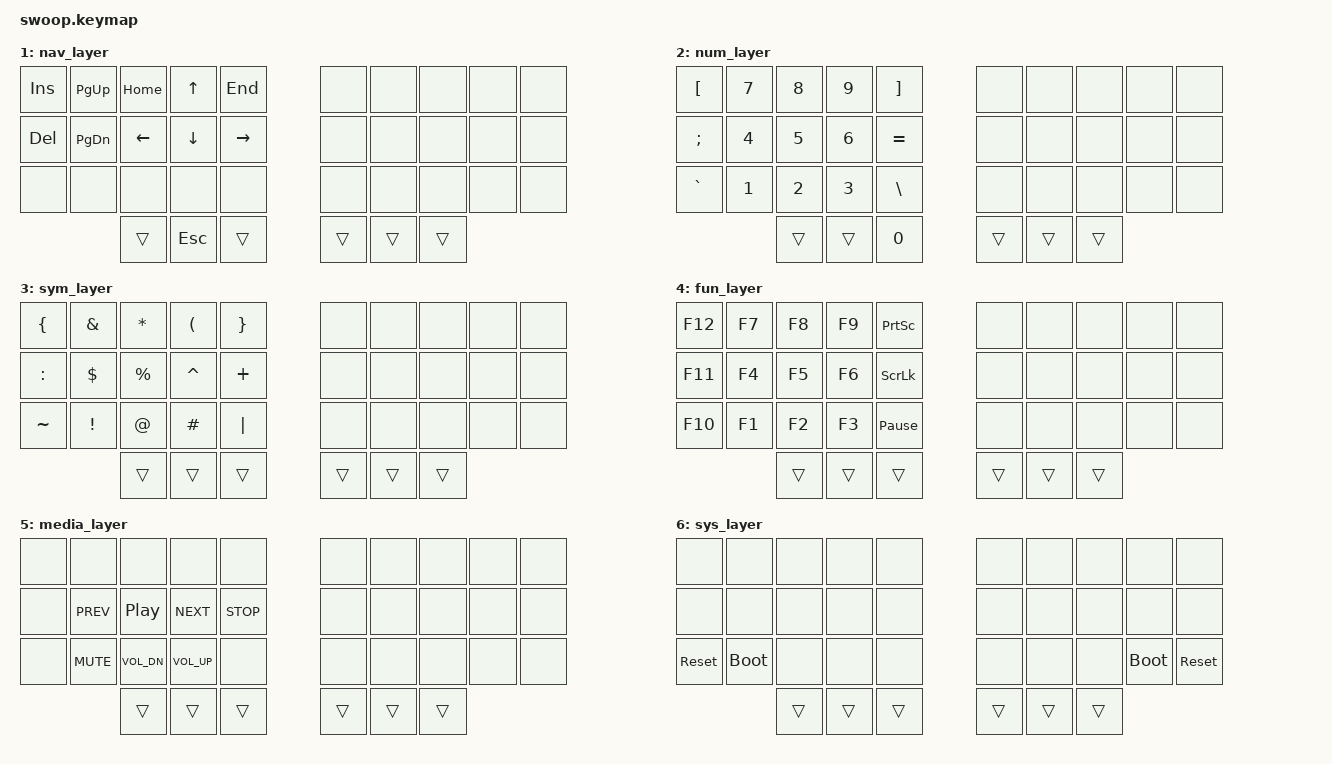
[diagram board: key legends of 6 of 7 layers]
/*
 * Copyright (c) 2023 The ZMK Contributors
 *
 * SPDX-License-Identifier: MIT
 */

#include <behaviors.dtsi>
#include <dt-bindings/zmk/keys.h>
#include <dt-bindings/zmk/bt.h>

// Layers
#define BASE 0
#define NAV  1
#define NUM  2
#define SYM  3
#define FUN  4
#define MEDIA 5
#define SYS  6  // System layer instead of Bluetooth

// Home row mods macro
#define HRML(k1,k2,k3,k4) &mt LCTRL k1  &mt LALT k2  &mt LGUI k3  &mt LSHFT k4
#define HRMR(k1,k2,k3,k4) &mt RSHFT k1  &mt RGUI k2  &mt RALT k3  &mt RCTRL k4

/ {
    behaviors {
        td0: tap_dance_0 {
            compatible = "zmk,behavior-tap-dance";
            label = "TAP_DANCE_0";
            #binding-cells = <0>;
            tapping-term-ms = <200>;
            bindings = <&mo FUN>, <&mo SYS>;
        };
    };

    keymap {
        compatible = "zmk,keymap";

        default_layer {
            // Miryoku-inspired with QWERTY home row
            // ┏━━━━━━━━━━━━━━━━━━━━━━━━━━━━━━━━━━━━━━━┓
            // ┃ Q    W    E    R    T    Y    U    I    O    P    ┃
            // ┃ A    S    D    F    G    H    J    K    L    ;    ┃
            // ┃ Z    X    C    V    B    N    M    ,    .    /    ┃
            // ┃           NAV  NUM  SPC  ENT  SYM  MEDIA         ┃
            // ┗━━━━━━━━━━━━━━━━━━━━━━━━━━━━━━━━━━━━━━━┛
            bindings = <
                &kp Q      &kp W      &kp E       &kp R       &kp T          &kp Y          &kp U       &kp I       &kp O      &kp P
                HRML(A,      S,         D,          F)         &kp G          &kp H          HRMR(J,      K,          L,         SEMI)
                &kp Z      &kp X      &kp C       &kp V       &kp B          &kp N          &kp M       &kp COMMA   &kp DOT    &kp SLASH
                                      &lt NAV ESC &lt NUM TAB  &kp SPACE      &kp RETURN     &lt SYM BSPC &td0
            >;
        };

        nav_layer {
            // Navigation layer
            // ┏━━━━━━━━━━━━━━━━━━━━━━━━━━━━━━━━━━━━━━━┓
            // ┃ INS    PG_UP  HOME   UP     END   __    __    __    __    __   ┃
            // ┃ DEL    PG_DN  LEFT   DOWN   RIGHT __    __    __    __    __   ┃
            // ┃ __     __     __     __     __    __    __    __    __    __   ┃
            // ┃              ▓▓▓▓▓  __     __    __    __    __                ┃
            // ┗━━━━━━━━━━━━━━━━━━━━━━━━━━━━━━━━━━━━━━━┛
            bindings = <
                &kp INS    &kp PG_UP  &kp HOME  &kp UP    &kp END       &none        &none        &none        &none        &none
                &kp DEL    &kp PG_DN  &kp LEFT  &kp DOWN  &kp RIGHT     &none        &none        &none        &none        &none
                &none      &none      &none     &none     &none         &none        &none        &none        &none        &none
                                      &trans    &kp ESC   &trans        &trans       &trans       &trans
            >;
        };

        num_layer {
            // Number layer
            // ┏━━━━━━━━━━━━━━━━━━━━━━━━━━━━━━━━━━━━━━━┓
            // ┃ [     7      8      9      ]     __    __    __    __    __   ┃
            // ┃ ;     4      5      6      =     __    __    __    __    __   ┃
            // ┃ `     1      2      3      \     __    __    __    __    __   ┃
            // ┃              __    ▓▓▓▓▓   0     __    __    __                ┃
            // ┗━━━━━━━━━━━━━━━━━━━━━━━━━━━━━━━━━━━━━━━┛
            bindings = <
                &kp LBKT   &kp N7     &kp N8    &kp N9    &kp RBKT      &none        &none        &none        &none        &none
                &kp SEMI   &kp N4     &kp N5    &kp N6    &kp EQUAL     &none        &none        &none        &none        &none
                &kp GRAVE  &kp N1     &kp N2    &kp N3    &kp BSLH      &none        &none        &none        &none        &none
                                      &trans    &trans    &kp N0        &trans       &trans       &trans
            >;
        };

        sym_layer {
            // Symbol layer
            // ┏━━━━━━━━━━━━━━━━━━━━━━━━━━━━━━━━━━━━━━━┓
            // ┃ {     &      *      (      }     __    __    __    __    __   ┃
            // ┃ :     $      %      ^      +     __    __    __    __    __   ┃
            // ┃ ~     !      @      #      |     __    __    __    __    __   ┃
            // ┃              __     __     __    __    ▓▓▓▓▓  __                ┃
            // ┗━━━━━━━━━━━━━━━━━━━━━━━━━━━━━━━━━━━━━━━┛
            bindings = <
                &kp LBRC   &kp AMPS   &kp ASTRK &kp LPAR  &kp RBRC      &none        &none        &none        &none        &none
                &kp COLON  &kp DLLR   &kp PRCNT &kp CARET &kp PLUS      &none        &none        &none        &none        &none
                &kp TILDE  &kp EXCL   &kp AT    &kp HASH  &kp PIPE      &none        &none        &none        &none        &none
                                      &trans    &trans    &trans        &trans       &trans       &trans
            >;
        };

        fun_layer {
            // Function layer
            // ┏━━━━━━━━━━━━━━━━━━━━━━━━━━━━━━━━━━━━━━━┓
            // ┃ F12   F7     F8     F9     PSCRN  __    __    __    __    __   ┃
            // ┃ F11   F4     F5     F6     SLCK   __    __    __    __    __   ┃
            // ┃ F10   F1     F2     F3     PAUSE  __    __    __    __    __   ┃
            // ┃               __     __     __     __    __    ▓▓▓▓▓             ┃
            // ┗━━━━━━━━━━━━━━━━━━━━━━━━━━━━━━━━━━━━━━━┛
            bindings = <
                &kp F12    &kp F7     &kp F8    &kp F9    &kp PSCRN     &none        &none        &none        &none        &none
                &kp F11    &kp F4     &kp F5    &kp F6    &kp SLCK      &none        &none        &none        &none        &none
                &kp F10    &kp F1     &kp F2    &kp F3    &kp PAUSE_BREAK &none      &none        &none        &none        &none
                                      &trans    &trans    &trans        &trans       &trans       &trans
            >;
        };

        media_layer {
            // Media layer
            // ┏━━━━━━━━━━━━━━━━━━━━━━━━━━━━━━━━━━━━━━━┓
            // ┃ __    __     __     __     __     __    __    __    __    __   ┃
            // ┃ __    PREV   PLAY   NEXT   STOP   __    __    __    __    __   ┃
            // ┃ __    MUTE   VOL_DN VOL_UP __     __    __    __    __    __   ┃
            // ┃               __     __     __     __    __    ▓▓▓▓▓             ┃
            // ┗━━━━━━━━━━━━━━━━━━━━━━━━━━━━━━━━━━━━━━━┛
            bindings = <
                &none      &none      &none     &none     &none         &none        &none        &none        &none        &none
                &none      &kp C_PREV &kp C_PP  &kp C_NEXT &kp C_STOP   &none        &none        &none        &none        &none
                &none      &kp C_MUTE &kp C_VOL_DN &kp C_VOL_UP &none   &none        &none        &none        &none        &none
                                      &trans    &trans    &trans        &trans       &trans       &trans
            >;
        };

        sys_layer {
            // System layer (replaces Bluetooth layer)
            // ┏━━━━━━━━━━━━━━━━━━━━━━━━━━━━━━━━━━━━━━━┓
            // ┃ __    __     __     __     __     __    __    __    __    __   ┃
            // ┃ __    __     __     __     __     __    __    __    __    __   ┃
            // ┃ RESET BOOTL  __     __     __     __    __    __    BOOTL RESET ┃
            // ┃               __     __     __     __    __    ▓▓▓▓▓             ┃
            // ┗━━━━━━━━━━━━━━━━━━━━━━━━━━━━━━━━━━━━━━━┛
            bindings = <
                &none      &none        &none        &none        &none        &none        &none &none &none &none
                &none      &none        &none        &none        &none        &none        &none &none &none &none
                &sys_reset &bootloader  &none        &none        &none        &none        &none &none &bootloader &sys_reset
                                        &trans       &trans       &trans       &trans       &trans &trans
            >;
        };
